# ADSP-2183xW_HPC register map
Vendor: Analog Devices; Series: ADSP-2183xW_HPC; File version: 3.0.3.517
CPU: 
Registers are 32-bit, read-write, reset 0x0 unless marked. A register's access mark holds for its fields unless they carry their own. Offsets are from the block's base; [hi:lo] are bit positions; {n}, {i} and the like mark numbered series.

## TRU0 — Trigger Routing Unit
Base 0x3108A000
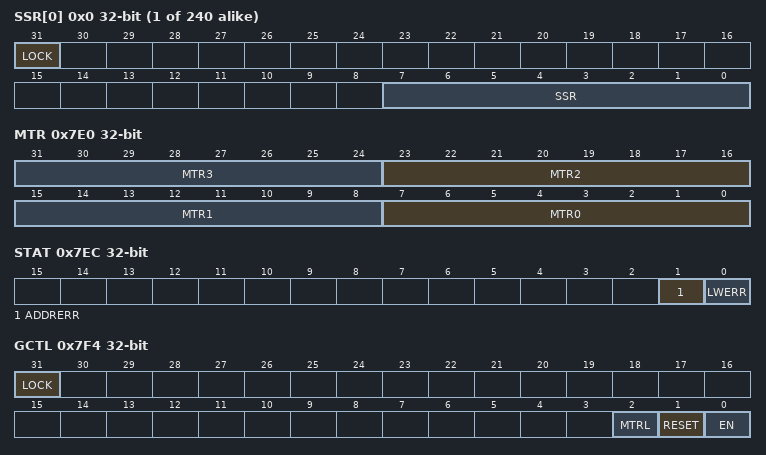
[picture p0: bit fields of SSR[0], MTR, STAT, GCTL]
{0x0+4i} SSR[{i}] (i=0..239) — Receiver Select Register
  [31] LOCK — SSRn Lock
  [7:0] SSR — SSRn Completer Select
0x7E0 MTR — Generator Trigger Register
  [8n+7:8n] MTR{n} (n=0..3) — Generator Trigger Register {n}
0x7E8 ERRADDR — Error Address Register
  [11:0] ADDR range 0x00000000..0x00000FFF — Error Address
0x7EC STAT — Status Information Register
  [1] ADDRERR — Address Error Status
  [0] LWERR — Lock Write Error Status
0x7F4 GCTL — Global Control Register
  [31] LOCK — GCTL Lock Bit
  [2] MTRL — MTR Lock Bit
  [1] RESET — Soft Reset
  [0] EN — Non-MMR Enable

## SPU0 — System Protection Unit
Base 0x3108B000
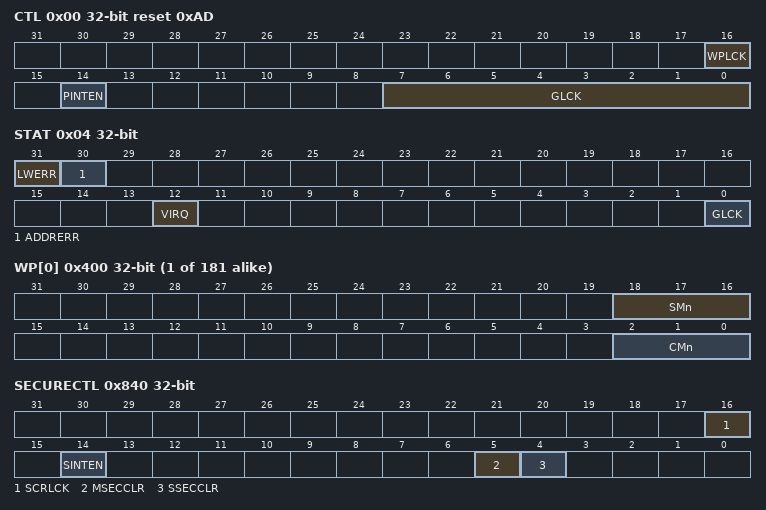
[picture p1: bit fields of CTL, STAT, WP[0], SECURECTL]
0x00 CTL reset 0xAD — Control Register
  [16] WPLCK — Write Protect Register Lock
  [14] PINTEN — Protection Violation Interrupt Enable
  [7:0] GLCK range 0x00000000..0x000000FF — Global Lock
0x04 STAT — Status Register
  [31] LWERR — Lock Write Error
  [30] ADDRERR — Address Error
  [12] VIRQ — Violation Interrupt Request
  [0] GLCK ro — Global Lock Status
{0x400+4i} WP[{i}] (i=0..180) — Write Protect Register n
  [18:16] SMn range 0x00000000..0x00000007 — System Requester x Write Protect Enable
  [2:0] CMn range 0x00000000..0x00000007 — Core Requester x Write Protect Enable
0x840 SECURECTL — Secure Control Register
  [16] SCRLCK — Secure Register Lock
  [14] SINTEN — Secure Violation Interrupt Enable
  [5] MSECCLR — Requester Secure Clear
  [4] SSECCLR — Completer Secure Clear
0x84C SECURECHK reset 0xFFFFFFFF — Secure Check Register
  [31:0] DATA ro — Read Data
{0x980+4i} SECUREC[{i}] reset 0x1 (i=0..2) — Secure Core Registers
  [0] CSEC — Core Secure
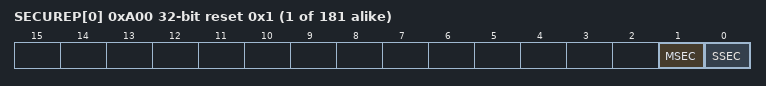
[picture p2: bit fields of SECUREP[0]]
{0xA00+4i} SECUREP[{i}] reset 0x1 (i=0..180) — Secure Peripheral Register
  [1] MSEC — Requester Secure Enable
  [0] SSEC — Completer Secure Enable

## RCU0 — Reset Control Unit
Base 0x3108C000
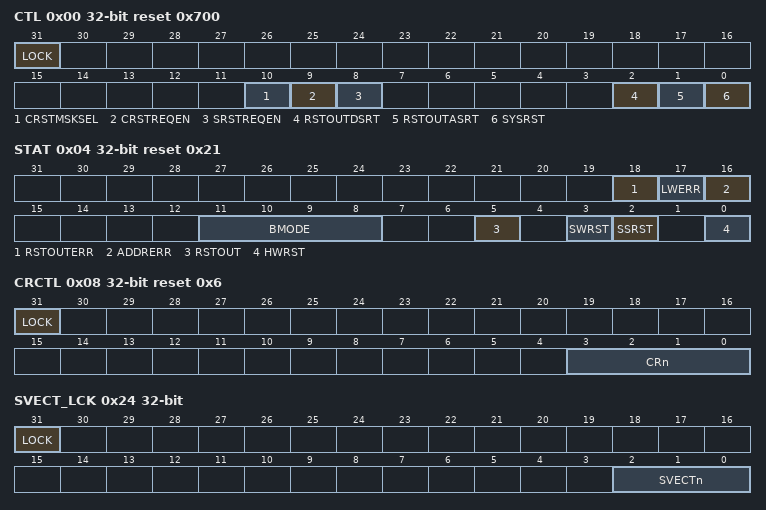
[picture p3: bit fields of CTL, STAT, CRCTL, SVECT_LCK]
0x00 CTL reset 0x700 — Control Register
  [31] LOCK
  [10] CRSTMSKSEL range 0x00000000..0x00000001 — Core Reset System Reset Mask Select
  [9] CRSTREQEN — Core Reset Request Enabled
  [8] SRSTREQEN — System Reset Request Enabled
  [2] RSTOUTDSRT — Reset Out Deassert
  [1] RSTOUTASRT — Reset Out Assert
  [0] SYSRST — System Reset
0x04 STAT reset 0x21 — Status Register
  [18] RSTOUTERR — Reset Out Error
  [17] LWERR — Lock Write Error
  [16] ADDRERR — Address Error
  [11:8] BMODE ro — Boot Mode
  [5] RSTOUT ro — Reset Out Status
  [3] SWRST — Software Reset
  [2] SSRST — System Source Reset
  [0] HWRST — Hardware Reset
0x08 CRCTL reset 0x6 — Core Reset Outputs Control Register
  [31] LOCK
  [3:0] CRn — Core Reset Outputs
0x0C CRSTAT reset 0x6 — Core Reset Outputs Status Register
  [3:0] CRn — Core Reset Outputs
0x18 SRRQSTAT — System Reset Request Status Register
  [7:0] SRRQ — System Reset Triggered by System Reset Request [n]
0x24 SVECT_LCK — SVECT Lock Register
  [31] LOCK
  [2:0] SVECTn range 0x00000000..0x00000007 — Lock SVECTn Registers
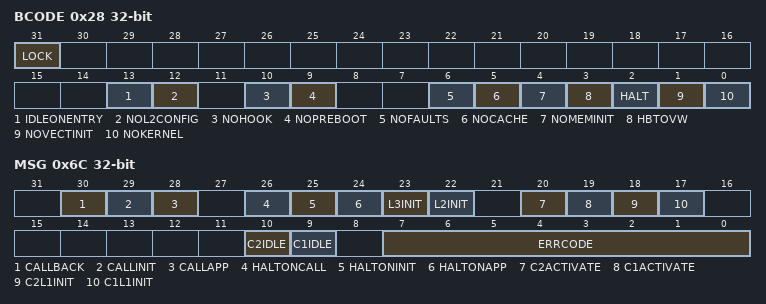
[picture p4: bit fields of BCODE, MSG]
0x28 BCODE — Boot Code Register
  [31] LOCK
  [13] IDLEONENTRY
  [12] NOL2CONFIG — No L2 Configuration
  [10] NOHOOK
  [9] NOPREBOOT
  [6] NOFAULTS
  [5] NOCACHE
  [4] NOMEMINIT — No Memory Initialization
  [3] HBTOVW — Execute Wakeup
  [2] HALT
  [1] NOVECTINIT — No Vector Initialize
  [0] NOKERNEL — No Boot Kernel
0x30 SVECT1 reset 0x202000E4 — Software Vector Register 1
  [31:0] VALUE range 0x00000000..0xFFFFFFFF — Reset Vector
0x34 SVECT2 reset 0x701 — Software Vector Register 2
  [31:0] VALUE range 0x00000000..0xFFFFFFFF — Reset Vector
0x6C MSG — Message Register
  [30] CALLBACK — Callback Call Flag
  [29] CALLINIT — Call Initcode Flag
  [28] CALLAPP — Call Application Flag
  [26] HALTONCALL — Halt on Callback Call
  [25] HALTONINIT — Halt on Initcode Call
  [24] HALTONAPP — Halt on Application Call
  [23] L3INIT — L3 Initialized
  [22] L2INIT — L2 Initialized
  [20] C2ACTIVATE range 0x00000000..0x00000001 — Core 2 Activated
  [19] C1ACTIVATE range 0x00000000..0x00000001 — Core 1 Activated
  [18] C2L1INIT range 0x00000000..0x00000001 — Core 2 L1 Initialized
  [17] C1L1INIT — Core 1 L1 Initialized
  [10] C2IDLE range 0x00000000..0x00000001 — Core 2 Idle
  [9] C1IDLE range 0x00000000..0x00000001 — Core 1 Idle
  [7:0] ERRCODE range 0x00000000..0x000000FF — ROM Error Code
0x70 MSG_SET — Message Set Bits Register
  [31:0] SET range 0x00000000..0xFFFFFFFF — Set Message Bits
0x74 MSG_CLR — Message Clear Bits Register
  [31:0] CLR range 0x00000000..0xFFFFFFFF — Clear MSG Register Bits
